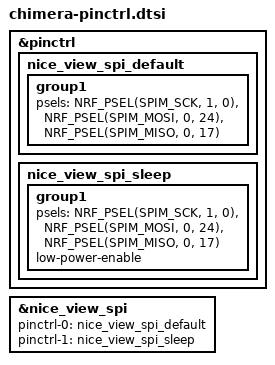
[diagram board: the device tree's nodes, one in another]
#include <dt-bindings/led/led.h>

&pinctrl {
    nice_view_spi_default: nice_view_spi_default {
        group1 {
            psels = <NRF_PSEL(SPIM_SCK, 1, 0)>,
                <NRF_PSEL(SPIM_MOSI, 0, 24)>,
                <NRF_PSEL(SPIM_MISO, 0, 17)>;
        };
    };
    nice_view_spi_sleep: nice_view_spi_sleep {
        group1 {
            psels = <NRF_PSEL(SPIM_SCK, 1, 0)>,
                <NRF_PSEL(SPIM_MOSI, 0, 24)>,
                <NRF_PSEL(SPIM_MISO, 0, 17)>;
            low-power-enable;
        };
    };
};

&nice_view_spi {
    pinctrl-0 = <&nice_view_spi_default>;
    pinctrl-1 = <&nice_view_spi_sleep>;
    pinctrl-names = "default", "sleep";
};
